AUTOSAR XML (schema 00044)
package /E40_Platform_System_SystemPackage/Components
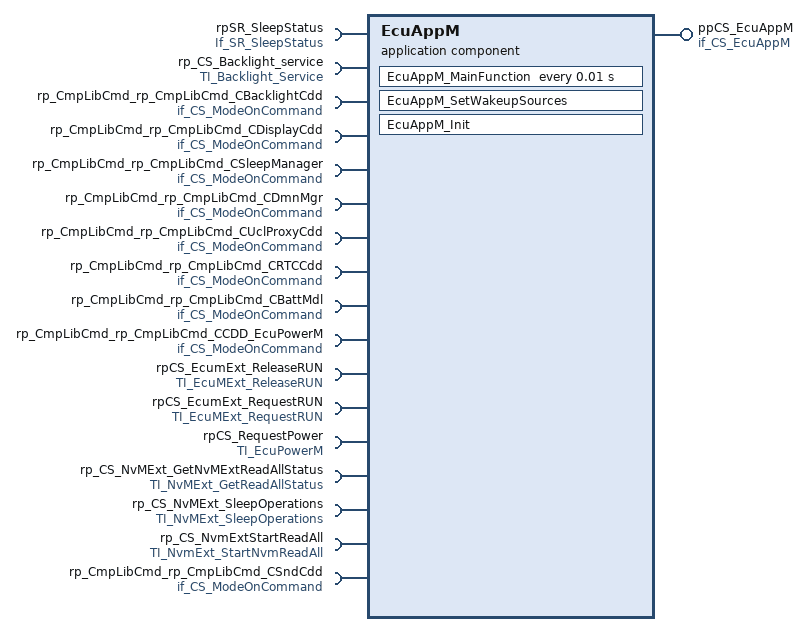
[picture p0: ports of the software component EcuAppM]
  application sw component type EcuAppM
    provide port ppCS_EcuAppM: provided-com-specs=[{operation=EcuAppM_SetWakeupSources, queue-length=1}, {operation=Init, queue-length=1}], provided-interface=if_CS_EcuAppM
    17 x require port:
      rpSR_SleepStatus: nonqueued-receiver-com-spec{data-element=SleepManager_SleepStatus, init-value=constant-reference=EcuAppMSleepManager_SleepStatusValue0}, required-interface=If_SR_SleepStatus
      rp_CS_Backlight_service: required-com-specs=[GetBrightnessValue, GetThermalValue, SetBrightnessValue], required-interface=TI_Backlight_Service
      rp_CmpLibCmd_rp_CmpLibCmd_CBacklightCdd: client-com-spec=Impl_OnCommand, required-interface=if_CS_ModeOnCommand
      rp_CmpLibCmd_rp_CmpLibCmd_CDisplayCdd: client-com-spec=Impl_OnCommand, required-interface=if_CS_ModeOnCommand
      rp_CmpLibCmd_rp_CmpLibCmd_CSleepManager: client-com-spec=Impl_OnCommand, required-interface=if_CS_ModeOnCommand
      rp_CmpLibCmd_rp_CmpLibCmd_CDmnMgr: client-com-spec=Impl_OnCommand, required-interface=if_CS_ModeOnCommand
      rp_CmpLibCmd_rp_CmpLibCmd_CUclProxyCdd: client-com-spec=Impl_OnCommand, required-interface=if_CS_ModeOnCommand
      rp_CmpLibCmd_rp_CmpLibCmd_CRTCCdd: client-com-spec=Impl_OnCommand, required-interface=if_CS_ModeOnCommand
      rp_CmpLibCmd_rp_CmpLibCmd_CBattMdl: client-com-spec=Impl_OnCommand, required-interface=if_CS_ModeOnCommand
      rp_CmpLibCmd_rp_CmpLibCmd_CCDD_EcuPowerM: client-com-spec=Impl_OnCommand, required-interface=if_CS_ModeOnCommand
      rpCS_EcumExt_ReleaseRUN: client-com-spec=ReleaseRUN, required-interface=TI_EcuMExt_ReleaseRUN
      rpCS_EcumExt_RequestRUN: client-com-spec=RequestRUN, required-interface=TI_EcuMExt_RequestRUN
      rpCS_RequestPower: required-com-specs=[EcuPowerM_GetDeviceStatus, EcuPowerM_RequestPower], required-interface=TI_EcuPowerM
      rp_CS_NvMExt_GetNvMExtReadAllStatus: client-com-spec=NvmExt_GetNvMReadAllStatus, required-interface=TI_NvMExt_GetReadAllStatus
      rp_CS_NvMExt_SleepOperations: required-com-specs=[NvMExt_CancelSleep, NvMExt_ReadytoSleep, NvMExt_RequestSleep], required-interface=TI_NvMExt_SleepOperations
      rp_CS_NvmExtStartReadAll: client-com-spec=NvMExt_ReadAll, required-interface=TI_NvmExt_StartNvmReadAll
      rp_CmpLibCmd_rp_CmpLibCmd_CSndCdd: client-com-spec=Impl_OnCommand, required-interface=if_CS_ModeOnCommand
    behavior IB_EcuAppM
      operation invoked event OIE_ppCS_EcuAppM_EcuAppM_SetWakeupSourcesTrigByEcuAppM_SetWakeupSources: start-on-event=EcuAppM_SetWakeupSources, operation=ppCS_EcuAppM.EcuAppM_SetWakeupSources
      operation invoked event OIE_ppCS_EcuAppM_EcuAppM_InitTrigByInit: start-on-event=EcuAppM_Init, operation=ppCS_EcuAppM.Init
      timing event TEEcuAppM_MainFunction: start-on-event=EcuAppM_MainFunction, period=0.01
      port-api-options:
        enable-take-address=false, indirect-api=false, port=ppCS_EcuAppM
        enable-take-address=false, indirect-api=false, port=rpSR_SleepStatus
        enable-take-address=false, indirect-api=false, port=rp_CS_Backlight_service
        enable-take-address=false, indirect-api=false, port=rp_CmpLibCmd_rp_CmpLibCmd_CBacklightCdd
        enable-take-address=false, indirect-api=false, port=rp_CmpLibCmd_rp_CmpLibCmd_CDisplayCdd
        enable-take-address=false, indirect-api=false, port=rp_CmpLibCmd_rp_CmpLibCmd_CSleepManager
        enable-take-address=false, indirect-api=false, port=rp_CmpLibCmd_rp_CmpLibCmd_CDmnMgr
        enable-take-address=false, indirect-api=false, port=rp_CmpLibCmd_rp_CmpLibCmd_CUclProxyCdd
        enable-take-address=false, indirect-api=false, port=rp_CmpLibCmd_rp_CmpLibCmd_CRTCCdd
        enable-take-address=false, indirect-api=false, port=rp_CmpLibCmd_rp_CmpLibCmd_CBattMdl
        enable-take-address=false, indirect-api=false, port=rp_CmpLibCmd_rp_CmpLibCmd_CCDD_EcuPowerM
        enable-take-address=false, indirect-api=false, port=rpCS_EcumExt_ReleaseRUN
        enable-take-address=false, indirect-api=false, port=rpCS_EcumExt_RequestRUN
        enable-take-address=false, indirect-api=false, port=rpCS_RequestPower
        enable-take-address=false, indirect-api=false, port=rp_CS_NvMExt_GetNvMExtReadAllStatus
        enable-take-address=false, indirect-api=false, port=rp_CS_NvMExt_SleepOperations
        enable-take-address=false, indirect-api=false, port=rp_CS_NvmExtStartReadAll
        enable-take-address=false, indirect-api=false, port=rp_CmpLibCmd_rp_CmpLibCmd_CSndCdd
      runnable EcuAppM_SetWakeupSources: can-be-invoked-concurrently=true
        data-receive-point-by-arguments:
          access DRA_rpSR_SleepStatus_SleepManager_SleepStatus: accessed-variable=rpSR_SleepStatus.SleepManager_SleepStatus
        21 x sync call:
          OA_rp_CS_Backlight_service_SetBrightnessValue: operation=rp_CS_Backlight_service.SetBrightnessValue
          OA_rp_CS_Backlight_service_GetBrightnessValue: operation=rp_CS_Backlight_service.GetBrightnessValue
          OA_rp_CS_Backlight_service_GetThermalValue: operation=rp_CS_Backlight_service.GetThermalValue
          OA_rp_CmpLibCmd_rp_CmpLibCmd_CBacklightCdd_Impl_OnCommand: operation=rp_CmpLibCmd_rp_CmpLibCmd_CBacklightCdd.Impl_OnCommand
          OA_rp_CmpLibCmd_rp_CmpLibCmd_CDisplayCdd_Impl_OnCommand: operation=rp_CmpLibCmd_rp_CmpLibCmd_CDisplayCdd.Impl_OnCommand
          OA_rp_CmpLibCmd_rp_CmpLibCmd_CSleepManager_Impl_OnCommand: operation=rp_CmpLibCmd_rp_CmpLibCmd_CSleepManager.Impl_OnCommand
          OA_rp_CmpLibCmd_rp_CmpLibCmd_CDmnMgr_Impl_OnCommand: operation=rp_CmpLibCmd_rp_CmpLibCmd_CDmnMgr.Impl_OnCommand
          OA_rp_CmpLibCmd_rp_CmpLibCmd_CUclProxyCdd_Impl_OnCommand: operation=rp_CmpLibCmd_rp_CmpLibCmd_CUclProxyCdd.Impl_OnCommand
          OA_rp_CmpLibCmd_rp_CmpLibCmd_CRTCCdd_Impl_OnCommand: operation=rp_CmpLibCmd_rp_CmpLibCmd_CRTCCdd.Impl_OnCommand
          OA_rp_CmpLibCmd_rp_CmpLibCmd_CBattMdl_Impl_OnCommand: operation=rp_CmpLibCmd_rp_CmpLibCmd_CBattMdl.Impl_OnCommand
          OA_rp_CmpLibCmd_rp_CmpLibCmd_CCDD_EcuPowerM_Impl_OnCommand: operation=rp_CmpLibCmd_rp_CmpLibCmd_CCDD_EcuPowerM.Impl_OnCommand
          OA_rpCS_EcumExt_ReleaseRUN_ReleaseRUN: operation=rpCS_EcumExt_ReleaseRUN.ReleaseRUN
          OA_rpCS_EcumExt_RequestRUN_RequestRUN: operation=rpCS_EcumExt_RequestRUN.RequestRUN
          OA_rpCS_RequestPower_EcuPowerM_RequestPower: operation=rpCS_RequestPower.EcuPowerM_RequestPower
          OA_rpCS_RequestPower_EcuPowerM_GetDeviceStatus: operation=rpCS_RequestPower.EcuPowerM_GetDeviceStatus
          OA_rp_CS_NvMExt_GetNvMExtReadAllStatus_NvmExt_GetNvMReadAllStatus: operation=rp_CS_NvMExt_GetNvMExtReadAllStatus.NvmExt_GetNvMReadAllStatus
          OA_rp_CS_NvMExt_SleepOperations_NvMExt_ReadytoSleep: operation=rp_CS_NvMExt_SleepOperations.NvMExt_ReadytoSleep
          OA_rp_CS_NvMExt_SleepOperations_NvMExt_RequestSleep: operation=rp_CS_NvMExt_SleepOperations.NvMExt_RequestSleep
          OA_rp_CS_NvMExt_SleepOperations_NvMExt_CancelSleep: operation=rp_CS_NvMExt_SleepOperations.NvMExt_CancelSleep
          OA_rp_CS_NvmExtStartReadAll_NvMExt_ReadAll: operation=rp_CS_NvmExtStartReadAll.NvMExt_ReadAll
          OA_rp_CmpLibCmd_rp_CmpLibCmd_CSndCdd_Impl_OnCommand: operation=rp_CmpLibCmd_rp_CmpLibCmd_CSndCdd.Impl_OnCommand
      runnable EcuAppM_Init: can-be-invoked-concurrently=true
        data-receive-point-by-arguments:
          access DRA_rpSR_SleepStatus_SleepManager_SleepStatus: accessed-variable=rpSR_SleepStatus.SleepManager_SleepStatus
        21 x sync call:
          OA_rp_CS_Backlight_service_SetBrightnessValue: operation=rp_CS_Backlight_service.SetBrightnessValue
          OA_rp_CS_Backlight_service_GetBrightnessValue: operation=rp_CS_Backlight_service.GetBrightnessValue
          OA_rp_CS_Backlight_service_GetThermalValue: operation=rp_CS_Backlight_service.GetThermalValue
          OA_rp_CmpLibCmd_rp_CmpLibCmd_CBacklightCdd_Impl_OnCommand: operation=rp_CmpLibCmd_rp_CmpLibCmd_CBacklightCdd.Impl_OnCommand
          OA_rp_CmpLibCmd_rp_CmpLibCmd_CDisplayCdd_Impl_OnCommand: operation=rp_CmpLibCmd_rp_CmpLibCmd_CDisplayCdd.Impl_OnCommand
          OA_rp_CmpLibCmd_rp_CmpLibCmd_CSleepManager_Impl_OnCommand: operation=rp_CmpLibCmd_rp_CmpLibCmd_CSleepManager.Impl_OnCommand
          OA_rp_CmpLibCmd_rp_CmpLibCmd_CDmnMgr_Impl_OnCommand: operation=rp_CmpLibCmd_rp_CmpLibCmd_CDmnMgr.Impl_OnCommand
          OA_rp_CmpLibCmd_rp_CmpLibCmd_CUclProxyCdd_Impl_OnCommand: operation=rp_CmpLibCmd_rp_CmpLibCmd_CUclProxyCdd.Impl_OnCommand
          OA_rp_CmpLibCmd_rp_CmpLibCmd_CRTCCdd_Impl_OnCommand: operation=rp_CmpLibCmd_rp_CmpLibCmd_CRTCCdd.Impl_OnCommand
          OA_rp_CmpLibCmd_rp_CmpLibCmd_CBattMdl_Impl_OnCommand: operation=rp_CmpLibCmd_rp_CmpLibCmd_CBattMdl.Impl_OnCommand
          OA_rp_CmpLibCmd_rp_CmpLibCmd_CCDD_EcuPowerM_Impl_OnCommand: operation=rp_CmpLibCmd_rp_CmpLibCmd_CCDD_EcuPowerM.Impl_OnCommand
          OA_rpCS_EcumExt_ReleaseRUN_ReleaseRUN: operation=rpCS_EcumExt_ReleaseRUN.ReleaseRUN
          OA_rpCS_EcumExt_RequestRUN_RequestRUN: operation=rpCS_EcumExt_RequestRUN.RequestRUN
          OA_rpCS_RequestPower_EcuPowerM_RequestPower: operation=rpCS_RequestPower.EcuPowerM_RequestPower
          OA_rpCS_RequestPower_EcuPowerM_GetDeviceStatus: operation=rpCS_RequestPower.EcuPowerM_GetDeviceStatus
          OA_rp_CS_NvMExt_GetNvMExtReadAllStatus_NvmExt_GetNvMReadAllStatus: operation=rp_CS_NvMExt_GetNvMExtReadAllStatus.NvmExt_GetNvMReadAllStatus
          OA_rp_CS_NvMExt_SleepOperations_NvMExt_ReadytoSleep: operation=rp_CS_NvMExt_SleepOperations.NvMExt_ReadytoSleep
          OA_rp_CS_NvMExt_SleepOperations_NvMExt_RequestSleep: operation=rp_CS_NvMExt_SleepOperations.NvMExt_RequestSleep
          OA_rp_CS_NvMExt_SleepOperations_NvMExt_CancelSleep: operation=rp_CS_NvMExt_SleepOperations.NvMExt_CancelSleep
          OA_rp_CS_NvmExtStartReadAll_NvMExt_ReadAll: operation=rp_CS_NvmExtStartReadAll.NvMExt_ReadAll
          OA_rp_CmpLibCmd_rp_CmpLibCmd_CSndCdd_Impl_OnCommand: operation=rp_CmpLibCmd_rp_CmpLibCmd_CSndCdd.Impl_OnCommand
      runnable EcuAppM_MainFunction: can-be-invoked-concurrently=true
        data-receive-point-by-arguments:
          access DRA_rpSR_SleepStatus_SleepManager_SleepStatus: accessed-variable=rpSR_SleepStatus.SleepManager_SleepStatus
        21 x sync call:
          OA_rp_CS_Backlight_service_SetBrightnessValue: operation=rp_CS_Backlight_service.SetBrightnessValue
          OA_rp_CS_Backlight_service_GetBrightnessValue: operation=rp_CS_Backlight_service.GetBrightnessValue
          OA_rp_CS_Backlight_service_GetThermalValue: operation=rp_CS_Backlight_service.GetThermalValue
          OA_rp_CmpLibCmd_rp_CmpLibCmd_CBacklightCdd_Impl_OnCommand: operation=rp_CmpLibCmd_rp_CmpLibCmd_CBacklightCdd.Impl_OnCommand
          OA_rp_CmpLibCmd_rp_CmpLibCmd_CDisplayCdd_Impl_OnCommand: operation=rp_CmpLibCmd_rp_CmpLibCmd_CDisplayCdd.Impl_OnCommand
          OA_rp_CmpLibCmd_rp_CmpLibCmd_CSleepManager_Impl_OnCommand: operation=rp_CmpLibCmd_rp_CmpLibCmd_CSleepManager.Impl_OnCommand
          OA_rp_CmpLibCmd_rp_CmpLibCmd_CDmnMgr_Impl_OnCommand: operation=rp_CmpLibCmd_rp_CmpLibCmd_CDmnMgr.Impl_OnCommand
          OA_rp_CmpLibCmd_rp_CmpLibCmd_CUclProxyCdd_Impl_OnCommand: operation=rp_CmpLibCmd_rp_CmpLibCmd_CUclProxyCdd.Impl_OnCommand
          OA_rp_CmpLibCmd_rp_CmpLibCmd_CRTCCdd_Impl_OnCommand: operation=rp_CmpLibCmd_rp_CmpLibCmd_CRTCCdd.Impl_OnCommand
          OA_rp_CmpLibCmd_rp_CmpLibCmd_CBattMdl_Impl_OnCommand: operation=rp_CmpLibCmd_rp_CmpLibCmd_CBattMdl.Impl_OnCommand
          OA_rp_CmpLibCmd_rp_CmpLibCmd_CCDD_EcuPowerM_Impl_OnCommand: operation=rp_CmpLibCmd_rp_CmpLibCmd_CCDD_EcuPowerM.Impl_OnCommand
          OA_rpCS_EcumExt_ReleaseRUN_ReleaseRUN: operation=rpCS_EcumExt_ReleaseRUN.ReleaseRUN
          OA_rpCS_EcumExt_RequestRUN_RequestRUN: operation=rpCS_EcumExt_RequestRUN.RequestRUN
          OA_rpCS_RequestPower_EcuPowerM_RequestPower: operation=rpCS_RequestPower.EcuPowerM_RequestPower
          OA_rpCS_RequestPower_EcuPowerM_GetDeviceStatus: operation=rpCS_RequestPower.EcuPowerM_GetDeviceStatus
          OA_rp_CS_NvMExt_GetNvMExtReadAllStatus_NvmExt_GetNvMReadAllStatus: operation=rp_CS_NvMExt_GetNvMExtReadAllStatus.NvmExt_GetNvMReadAllStatus
          OA_rp_CS_NvMExt_SleepOperations_NvMExt_ReadytoSleep: operation=rp_CS_NvMExt_SleepOperations.NvMExt_ReadytoSleep
          OA_rp_CS_NvMExt_SleepOperations_NvMExt_RequestSleep: operation=rp_CS_NvMExt_SleepOperations.NvMExt_RequestSleep
          OA_rp_CS_NvMExt_SleepOperations_NvMExt_CancelSleep: operation=rp_CS_NvMExt_SleepOperations.NvMExt_CancelSleep
          OA_rp_CS_NvmExtStartReadAll_NvMExt_ReadAll: operation=rp_CS_NvmExtStartReadAll.NvMExt_ReadAll
          OA_rp_CmpLibCmd_rp_CmpLibCmd_CSndCdd_Impl_OnCommand: operation=rp_CmpLibCmd_rp_CmpLibCmd_CSndCdd.Impl_OnCommand
  swc implementation IMPL_EcuAppM: behavior=IB_EcuAppM
